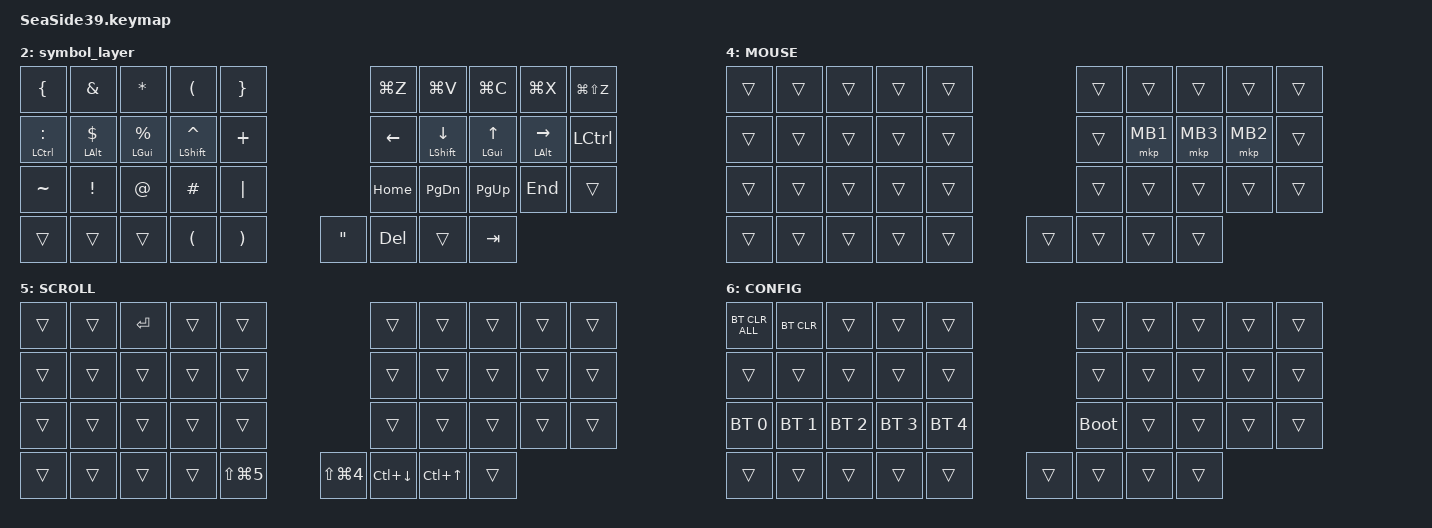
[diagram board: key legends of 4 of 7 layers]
#include <behaviors.dtsi>
#include <dt-bindings/zmk/bt.h>
#include <dt-bindings/zmk/keys.h>
#include <dt-bindings/zmk/pointing.h>

#define MOUSE 4
#define SCROLL 5
#define NUM 6

&mt {
    flavor = "balanced";
    quick-tap-ms = <300>;
};

&lt {
    flavor = "balanced";
    quick-tap-ms = <300>;
};

/ {
    combos { compatible = "zmk,combos"; };

    macros {
        to_layer_0: to_layer_0 {
            compatible = "zmk,behavior-macro-one-param";
            #binding-cells = <1>;
            bindings = <&to 0 &macro_param_1to1 &kp MACRO_PLACEHOLDER>;
            label = "TO_LAYER_0";
        };
    };

    behaviors {
        lt_to_layer_0: lt_to_layer_0 {
            compatible = "zmk,behavior-hold-tap";
            label = "LAYER_TAP_TO_0";
            bindings = <&mo>, <&to_layer_0>;

            #binding-cells = <2>;
            tapping-term-ms = <200>;
        };
        td0: tap_dance_0 {
            compatible = "zmk,behavior-tap-dance";
            #binding-cells = <0>;
            tapping-term-ms = <200>;
            bindings = <&kp Q>, <&kp ESC>;
        };
        hm: homerow_mods {
            compatible = "zmk,behavior-hold-tap";
            #binding-cells = <2>;
            tapping-term-ms = <200>;
            quick-tap-ms = <0>;
            flavor = "tap-preferred";
            bindings = <&kp>, <&kp>;
        };
    };

    keymap {
        compatible = "zmk,keymap";

        default_layer {
            bindings = <
    &td0         &kp W       &kp E       &kp R            &kp T                                       &kp Y       &kp U        &kp I       &kp O       &kp P
    &hm LCTRL A  &hm LALT S  &hm LGUI D  &hm LSHFT F      &kp G                                       &kp H       &hm LSHFT J  &hm LGUI K  &hm LALT L  &hm LCTRL MINUS
    &kp Z        &kp X       &kp C       &kp V            &kp B                                       &kp N       &kp M        &kp COMMA   &kp DOT     &kp FSLH
    &kp LCTRL    &kp LALT    &kp LGUI    &mt LSHFT LANG2  &lt 2 SPACE &lt 1 LANG1         &lt 2 BSPC  &lt 1 RET   &lt 3 TAB    &lt 5 ESCAPE
            >;

            sensor-bindings = <&inc_dec_kp PG_UP PAGE_DOWN>;
        };

        navnum_layer {
            bindings = <
    &kp LBKT        &kp N7      &kp N8      &kp N9          &kp RBKT                                    &kp LC(LG(UP))      &kp LC(LG(LEFT))      &kp LA(LS(LG(EQUAL)))      &kp LC(LG(RIGHT))      &trans
    &hm LCTRL SEMI  &hm LALT N4 &hm LGUI N5 &hm LSHFT N6    &kp EQUAL                                   &kp LC(LG(DOWN))    &mkp MB1              &mkp MB3                   &mkp MB2               &kp LCTRL 
    &kp GRAVE       &kp N1      &kp N2      &kp N3          &kp BSLH                                    &kp LC(LEFT)        &kp LC(LA(LG(LEFT)))  &kp LC(LA(LG(EQUAL)))      &kp LC(LA(LG(RIGHT)))  &kp LC(RIGHT)
    &trans          &trans      &trans      &kp DOT         &kp N0                  &kp APOS            &kp DEL               &kp RET                    &kp TAB                &none
            >;
        };

        symbol_layer {
            bindings = <
    &kp LBRC        &kp AMPS        &kp ASTERISK    &kp LPAR            &kp RBRC                                    &kp LG(Z)           &kp LG(V)       &kp LG(C)    &kp LG(X)   &kp LG(LS(Z))
    &hm LCTRL COLON &hm LALT DLLR   &hm LGUI PRCNT  &hm LSHFT CARET     &kp PLUS                                    &kp LEFT            &hm LSHFT DOWN  &hm LGUI UP  &hm LALT RIGHT   &kp LCTRL
    &kp TILDE       &kp EXCL        &kp AT          &kp HASH            &kp PIPE                                    &kp HOME            &kp PG_DN       &kp PG_UP    &kp END    &trans
    &trans          &trans          &trans          &kp LPAR            &kp RPAR                &kp DOUBLE_QUOTES   &kp DEL         &trans       &kp TAB
            >;
        };

        ARROW {
            bindings = <
    &kp F12     &kp F7  &kp F8      &kp F9      &trans                                  &trans          &trans          &trans          &trans          &sys_reset
    &kp F11     &kp F4  &kp F5      &kp F6      &trans                                  &bt BT_SEL 0    &bt BT_SEL 1    &bt BT_SEL 2    &bt BT_SEL 3    &bt BT_SEL 4
    &kp F10     &kp F1  &kp F2      &kp F3      &trans                                  &bt BT_NXT      &bt BT_CLR_ALL  &bt BT_CLR      &trans          &bt BT_PRV
    &trans      &trans  &trans      &kp DEL     &lt 1 SPACE   &kp TAB         &kp BSPC  &kp RET         &kp TAB         &none
            >;

            sensor-bindings = <&inc_dec_kp LC(PAGE_UP) LC(PAGE_DOWN)>;
        };

        MOUSE {
            bindings = <
&trans  &trans  &trans  &trans  &trans                      &trans  &trans    &trans    &trans    &trans
&trans  &trans  &trans  &trans  &trans                      &trans  &mkp MB1  &mkp MB3  &mkp MB2  &trans
&trans  &trans  &trans  &trans  &trans                      &trans  &trans    &trans    &trans    &trans
&trans  &trans  &trans  &trans  &trans  &trans      &trans  &trans                                &trans
            >;
        };

        SCROLL {
            bindings = <
&trans  &trans  &kp ENTER  &trans  &trans                                            &trans            &trans  &trans  &trans  &trans
&trans  &trans  &trans     &trans  &trans                                            &trans            &trans  &trans  &trans  &trans
&trans  &trans  &trans     &trans  &trans                                            &trans            &trans  &trans  &trans  &trans
&trans  &trans  &trans     &trans  &kp LS(LG(N5))  &kp LS(LG(N4))      &kp LC(DOWN)  &kp LC(UP_ARROW)                          &trans
            >;
        };

        CONFIG {
            bindings = <
&bt BT_CLR_ALL  &bt BT_CLR    &trans        &trans        &trans                            &trans       &trans  &trans  &trans  &trans
&trans          &trans        &trans        &trans        &trans                            &trans       &trans  &trans  &trans  &trans
&bt BT_SEL 0    &bt BT_SEL 1  &bt BT_SEL 2  &bt BT_SEL 3  &bt BT_SEL 4                      &bootloader  &trans  &trans  &trans  &trans
&trans          &trans        &trans        &trans        &trans        &trans      &trans  &trans                               &trans
            >;
        };
    };
};
